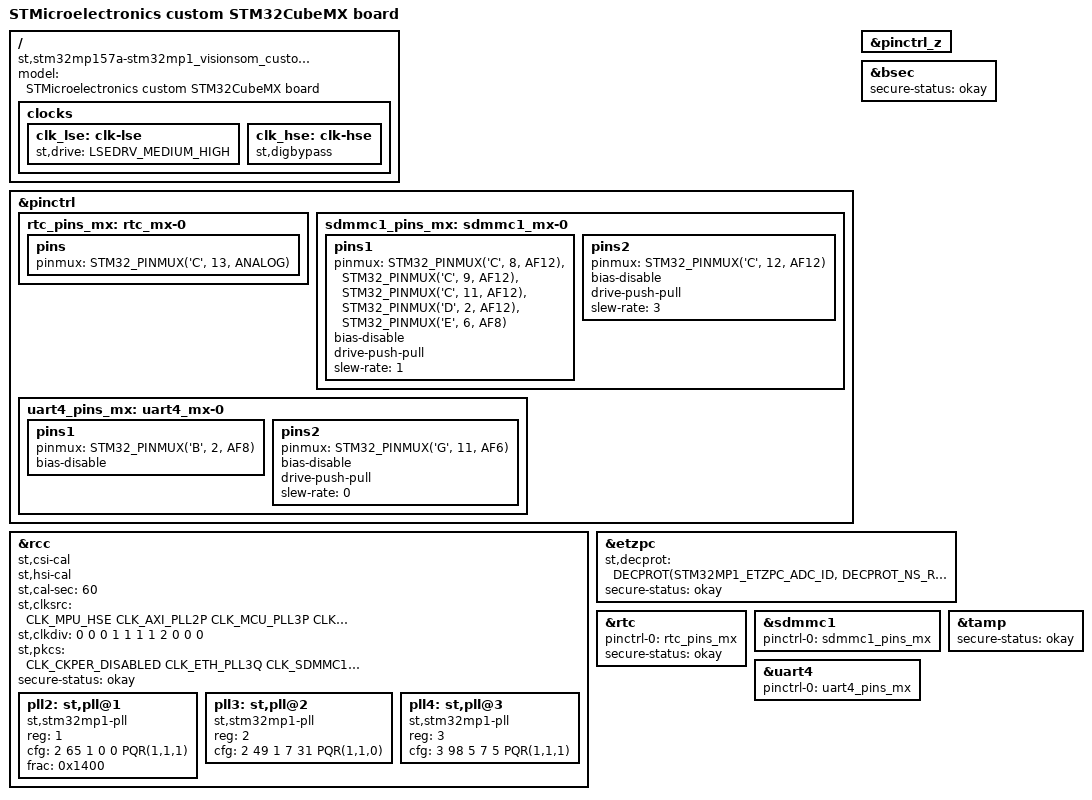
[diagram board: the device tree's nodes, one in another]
/* SPDX-License-Identifier: (GPL-2.0+ OR BSD-3-Clause) */
/*
 * Copyright (C) STMicroelectronics 2021 - All Rights Reserved
 * Author: STM32CubeMX code generation for STMicroelectronics.
 */

/* For more information on Device Tree configuration, please refer to
 * https://wiki.st.com/stm32mpu/wiki/Category:Device_tree_configuration
 */

/dts-v1/;
#include <dt-bindings/pinctrl/stm32-pinfunc.h>
#include <dt-bindings/clock/stm32mp1-clksrc.h>
#include <dt-bindings/soc/st,stm32-etzpc.h>
#include "stm32mp15-mx.dtsi"

#include "stm32mp157.dtsi"
#include "stm32mp15xa.dtsi"
#include "stm32mp15xxab-pinctrl.dtsi"
#include "stm32mp15-ddr.dtsi"

/* USER CODE BEGIN includes */
/* USER CODE END includes */

/ {
	model = "STMicroelectronics custom STM32CubeMX board";
	compatible = "st,stm32mp157a-stm32mp1_visionsom_custom_board_cubemx-mx", "st,stm32mp157";

	/* USER CODE BEGIN root */
	/* USER CODE END root */

	clocks {
		/* USER CODE BEGIN clocks */
		/* USER CODE END clocks */

		clk_lse: clk-lse {
			st,drive = < LSEDRV_MEDIUM_HIGH >;

			/* USER CODE BEGIN clk_lse */
			/* USER CODE END clk_lse */
		};

		clk_hse: clk-hse {
			st,digbypass;

			/* USER CODE BEGIN clk_hse */
			/* USER CODE END clk_hse */
		};
	};

}; /*root*/

&pinctrl {
	rtc_pins_mx: rtc_mx-0 {
		pins {
			pinmux = <STM32_PINMUX('C', 13, ANALOG)>; /* RTC_LSCO */
		};
	};

	sdmmc1_pins_mx: sdmmc1_mx-0 {
		pins1 {
			pinmux = <STM32_PINMUX('C', 8, AF12)>, /* SDMMC1_D0 */
					 <STM32_PINMUX('C', 9, AF12)>, /* SDMMC1_D1 */
					 <STM32_PINMUX('C', 11, AF12)>, /* SDMMC1_D3 */
					 <STM32_PINMUX('D', 2, AF12)>, /* SDMMC1_CMD */
					 <STM32_PINMUX('E', 6, AF8)>; /* SDMMC1_D2 */
			bias-disable;
			drive-push-pull;
			slew-rate = <1>;
		};
		pins2 {
			pinmux = <STM32_PINMUX('C', 12, AF12)>; /* SDMMC1_CK */
			bias-disable;
			drive-push-pull;
			slew-rate = <3>;
		};
	};

	uart4_pins_mx: uart4_mx-0 {
		pins1 {
			pinmux = <STM32_PINMUX('B', 2, AF8)>; /* UART4_RX */
			bias-disable;
		};
		pins2 {
			pinmux = <STM32_PINMUX('G', 11, AF6)>; /* UART4_TX */
			bias-disable;
			drive-push-pull;
			slew-rate = <0>;
		};
	};

	/* USER CODE BEGIN pinctrl */
	/* USER CODE END pinctrl */
};

&pinctrl_z {
	/* USER CODE BEGIN pinctrl_z */
	/* USER CODE END pinctrl_z */
};

&rcc {
	st,csi-cal;
	st,hsi-cal;
	st,cal-sec = <60>;
	st,clksrc = <
		CLK_MPU_HSE
		CLK_AXI_PLL2P
		CLK_MCU_PLL3P
		CLK_PLL12_HSE
		CLK_PLL3_HSE
		CLK_PLL4_HSE
		CLK_RTC_LSE
		CLK_MCO1_DISABLED
		CLK_MCO2_DISABLED
	>;
	st,clkdiv = <
		0 		/*MPU*/
		0 		/*AXI*/
		0 		/*MCU*/
		1 		/*APB1*/
		1 		/*APB2*/
		1 		/*APB3*/
		1 		/*APB4*/
		2 		/*APB5*/
		0 		/*RTC*/
		0 		/*MCO1*/
		0 		/*MCO2*/
	>;
	st,pkcs = <
		CLK_CKPER_DISABLED
		CLK_ETH_PLL3Q
		CLK_SDMMC12_PLL4P
		CLK_DSI_DSIPLL
		CLK_STGEN_HSI
		CLK_USBPHY_HSE
		CLK_SPI2S1_PLL4P
		CLK_SPI2S23_PLL4P
		CLK_SPI45_DISABLED
		CLK_SPI6_DISABLED
		CLK_I2C46_PCLK5
		CLK_SDMMC3_DISABLED
		CLK_USBO_USBPHY
		CLK_ADC_PLL4R
		CLK_CEC_DISABLED
		CLK_I2C12_DISABLED
		CLK_I2C35_DISABLED
		CLK_UART1_DISABLED
		CLK_UART24_PCLK1
		CLK_UART35_DISABLED
		CLK_UART6_DISABLED
		CLK_UART78_DISABLED
		CLK_SPDIF_DISABLED
		CLK_SAI1_DISABLED
		CLK_SAI2_DISABLED
		CLK_SAI3_DISABLED
		CLK_SAI4_DISABLED
		CLK_LPTIM1_DISABLED
		CLK_LPTIM23_DISABLED
		CLK_LPTIM45_DISABLED
	>;
	pll2:st,pll@1 {
		compatible = "st,stm32mp1-pll";
		reg = <1>;
		cfg = < 2 65 1 0 0 PQR(1,1,1) >;
		frac = < 0x1400 >;
	};
	pll3:st,pll@2 {
		compatible = "st,stm32mp1-pll";
		reg = <2>;
		cfg = < 2 49 1 7 31 PQR(1,1,0) >;
	};
	pll4:st,pll@3 {
		compatible = "st,stm32mp1-pll";
		reg = <3>;
		cfg = < 3 98 5 7 5 PQR(1,1,1) >;
	};
};

&bsec{
	status = "okay";
	secure-status = "okay";

	/* USER CODE BEGIN bsec */
	/* USER CODE END bsec */
};

&etzpc{
	st,decprot = <
	/*"Non Secured" peripherals*/
	DECPROT(STM32MP1_ETZPC_ADC_ID, DECPROT_NS_RW, DECPROT_UNLOCK)
	DECPROT(STM32MP1_ETZPC_DMA1_ID, DECPROT_NS_RW, DECPROT_UNLOCK)
	DECPROT(STM32MP1_ETZPC_DMAMUX_ID, DECPROT_NS_RW, DECPROT_UNLOCK)
	DECPROT(STM32MP1_ETZPC_ETH_ID, DECPROT_NS_RW, DECPROT_UNLOCK)
	DECPROT(STM32MP1_ETZPC_I2C4_ID, DECPROT_NS_RW, DECPROT_UNLOCK)
	DECPROT(STM32MP1_ETZPC_SPI1_ID, DECPROT_NS_RW, DECPROT_UNLOCK)
	DECPROT(STM32MP1_ETZPC_SPI3_ID, DECPROT_NS_RW, DECPROT_UNLOCK)
	DECPROT(STM32MP1_ETZPC_TIM4_ID, DECPROT_NS_RW, DECPROT_UNLOCK)
	DECPROT(STM32MP1_ETZPC_UART4_ID, DECPROT_NS_RW, DECPROT_UNLOCK)
	DECPROT(STM32MP1_ETZPC_OTG_ID, DECPROT_NS_RW, DECPROT_UNLOCK)
	DECPROT(STM32MP1_ETZPC_VREFBUF_ID, DECPROT_NS_RW, DECPROT_UNLOCK)
	/*"Secured" peripherals*/
	DECPROT(STM32MP1_ETZPC_DDRCTRL_ID, DECPROT_S_RW, DECPROT_UNLOCK)
	DECPROT(STM32MP1_ETZPC_DDRPHYC_ID, DECPROT_S_RW, DECPROT_UNLOCK)
	DECPROT(STM32MP1_ETZPC_STGENC_ID, DECPROT_S_RW, DECPROT_UNLOCK)
	/*"Mcu Isolation" peripherals*/
	DECPROT(STM32MP1_ETZPC_DMA2_ID, DECPROT_MCU_ISOLATION, DECPROT_UNLOCK)

	/*Restriction: following IDs are not managed  - please to use User-Section if needed:
		STM32MP1_ETZPC_SRAMx_ID, STM32MP1_ETZPC_RETRAM_ID, STM32MP1_ETZPC_BKPSRAM_ID*/

	/* USER CODE BEGIN etzpc_decprot */
		/*STM32CubeMX generates a basic and standard configuration for ETZPC.
		Additional device configurations can be added here if needed.
		"etzpc" node could be also overloaded in "addons" User-Section.*/
	/* USER CODE END etzpc_decprot */
	>;

	secure-status = "okay";

	/* USER CODE BEGIN etzpc */
	/* USER CODE END etzpc */
};

&rcc{
	status = "okay";
	secure-status = "okay";

	/* USER CODE BEGIN rcc */
	/* USER CODE END rcc */
};

&rtc{
	pinctrl-names = "default";
	pinctrl-0 = <&rtc_pins_mx>;
	status = "okay";
	secure-status = "okay";

	/* USER CODE BEGIN rtc */
	/* USER CODE END rtc */
};

&sdmmc1{
	pinctrl-names = "default";
	pinctrl-0 = <&sdmmc1_pins_mx>;
	status = "okay";

	/* USER CODE BEGIN sdmmc1 */
	/* USER CODE END sdmmc1 */
};

&tamp{
	status = "okay";
	secure-status = "okay";

	/* USER CODE BEGIN tamp */
	/* USER CODE END tamp */
};

&uart4{
	pinctrl-names = "default";
	pinctrl-0 = <&uart4_pins_mx>;
	status = "okay";

	/* USER CODE BEGIN uart4 */
	/* USER CODE END uart4 */
};

/* USER CODE BEGIN addons */
/* USER CODE END addons */

